# N32H49X register map
Vendor: Nsingtech Ltd.; File version: 1.0
Registers are 32-bit, read-write, reset 0x0 unless marked. A register's access mark holds for its fields unless they carry their own. Offsets are from the block's base; [hi:lo] are bit positions; {n}, {i} and the like mark numbered series.

## GPIOA — General purpose I/O
Base 0x4002C000
Same registers: GPIOB 0x4002C400, GPIOC 0x4002C800, GPIOD 0x4002CC00, GPIOE 0x4002D000, GPIOF 0x4002D400, GPIOG 0x4002D800
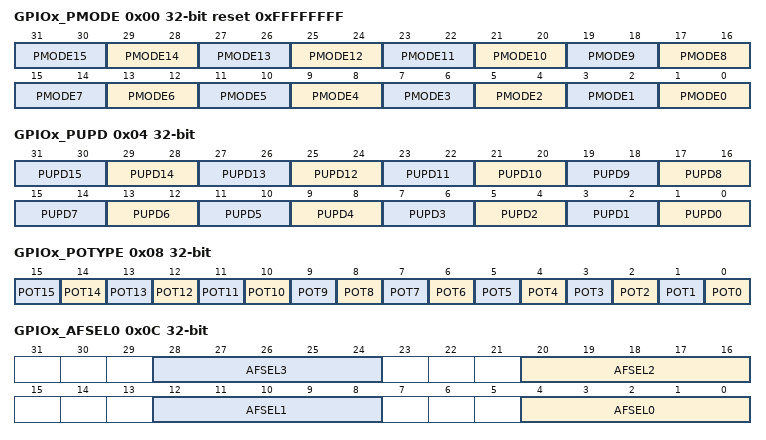
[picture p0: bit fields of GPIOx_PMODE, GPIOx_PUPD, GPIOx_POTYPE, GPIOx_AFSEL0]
0x00 GPIOx_PMODE reset 0xFFFFFFFF
  [2n+1:2n] PMODE{n} (n=0..15)
0x04 GPIOx_PUPD — GPIO pull-up/pull-down description register
  [2n+1:2n] PUPD{n} (n=0..15)
0x08 GPIOx_POTYPE — GPIO output type definition
  [n] POT{n} (n=0..15)
0x0C GPIOx_AFSEL0 — GPIO alternate function select register 0
  [8n+4:8n] AFSEL{n} (n=0..3)
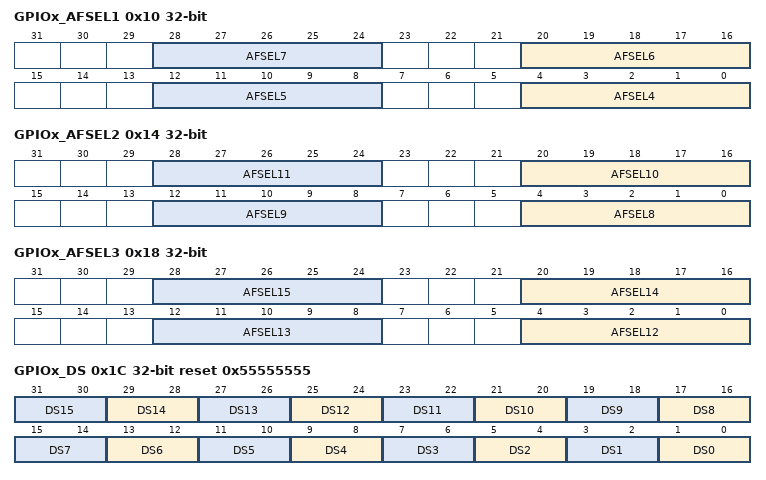
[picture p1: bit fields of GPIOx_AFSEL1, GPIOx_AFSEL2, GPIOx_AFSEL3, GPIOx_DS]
0x10 GPIOx_AFSEL1 — GPIO alternate function select register 1
  [8n-28:8n-32] AFSEL{n} (n=4..7)
0x14 GPIOx_AFSEL2 — GPIO alternate function select register 2
  [8n-60:8n-64] AFSEL{n} (n=8..11)
0x18 GPIOx_AFSEL3 — GPIO alternate function select register 3
  [8n-92:8n-96] AFSEL{n} (n=12..15)
0x1C GPIOx_DS reset 0x55555555 — GPIO driver strength configuration register
  [2n+1:2n] DS{n} (n=0..15)
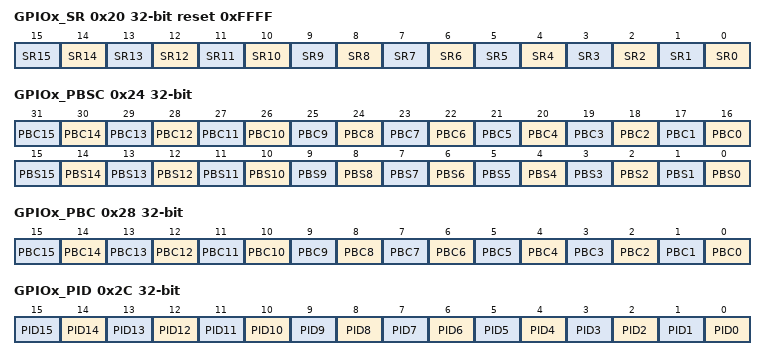
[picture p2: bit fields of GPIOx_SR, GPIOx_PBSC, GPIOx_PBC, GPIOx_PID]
0x20 GPIOx_SR reset 0xFFFF — GPIO slew rate configuration register
  [n] SR{n} (n=0..15)
0x24 GPIOx_PBSC wo — GPIO bit set/clear register
  [n+16] PBC{n} (n=0..15), [n] PBS{n} (n=0..15)
0x28 GPIOx_PBC wo — GPIO bit clear register
  [n] PBC{n} (n=0..15)
0x2C GPIOx_PID ro — GPIO input data register
  [n] PID{n} (n=0..15)
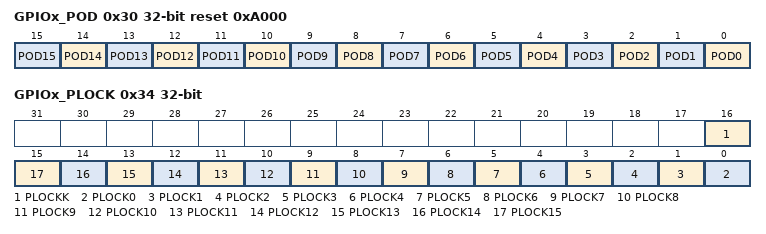
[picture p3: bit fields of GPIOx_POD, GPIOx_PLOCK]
0x30 GPIOx_POD reset 0xA000 — GPIO output data register
  [n] POD{n} (n=0..15)
0x34 GPIOx_PLOCK — GPIO configuration lock register
  [16] PLOCKK, [n] PLOCK{n} (n=0..15)

## GPIOH — General purpose I/O
Base 0x4002DC00
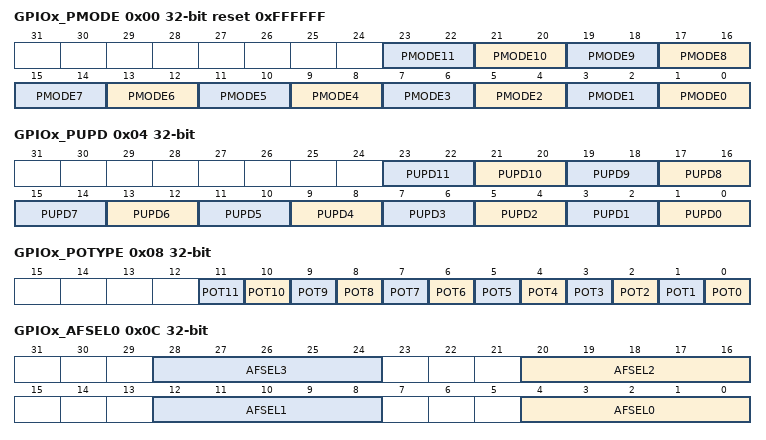
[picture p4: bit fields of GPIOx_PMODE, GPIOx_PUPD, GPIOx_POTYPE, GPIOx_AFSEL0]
0x00 GPIOx_PMODE reset 0xFFFFFF — GPIO mode description register
  [2n+1:2n] PMODE{n} (n=0..11)
0x04 GPIOx_PUPD — GPIO pull-up/pull-down description register
  [2n+1:2n] PUPD{n} (n=0..11)
0x08 GPIOx_POTYPE — GPIO output type definition
  [n] POT{n} (n=0..11)
0x0C GPIOx_AFSEL0 — GPIO alternate function select register 0
  [8n+4:8n] AFSEL{n} (n=0..3)
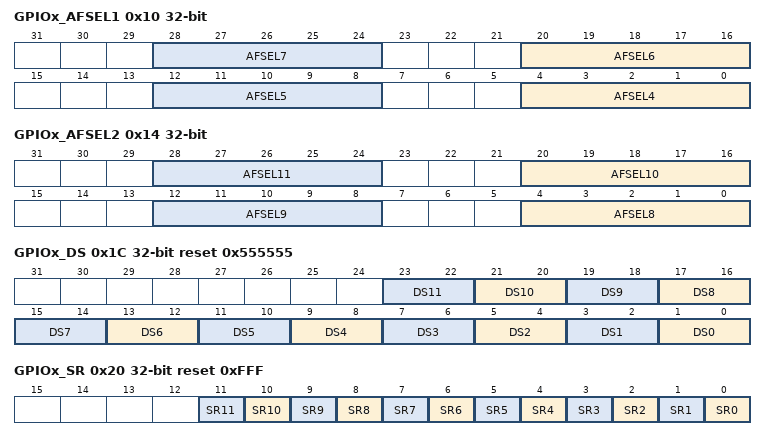
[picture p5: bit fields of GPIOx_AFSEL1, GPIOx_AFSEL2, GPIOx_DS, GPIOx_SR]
0x10 GPIOx_AFSEL1 — GPIO alternate function select register 1
  [8n-28:8n-32] AFSEL{n} (n=4..7)
0x14 GPIOx_AFSEL2 — GPIO alternate function select register 2
  [8n-60:8n-64] AFSEL{n} (n=8..11)
0x1C GPIOx_DS reset 0x555555 — GPIO driver strength configuration register
  [2n+1:2n] DS{n} (n=0..11)
0x20 GPIOx_SR reset 0xFFF — GPIO slew rate configuration register
  [n] SR{n} (n=0..11)
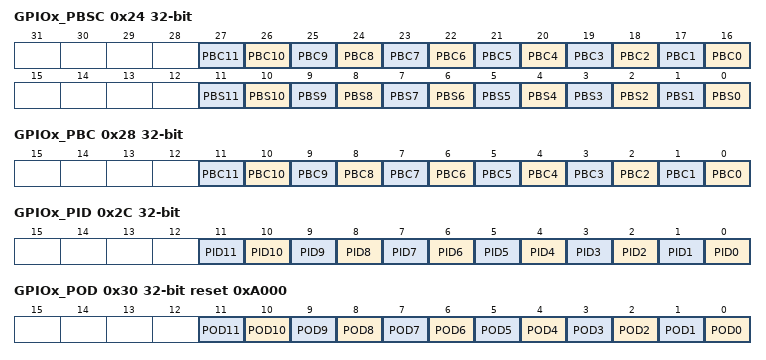
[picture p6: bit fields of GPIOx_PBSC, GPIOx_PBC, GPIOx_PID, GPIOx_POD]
0x24 GPIOx_PBSC wo — GPIO bit set/clear register
  [n+16] PBC{n} (n=0..11), [n] PBS{n} (n=0..11)
0x28 GPIOx_PBC wo — GPIO bit clear register
  [n] PBC{n} (n=0..11)
0x2C GPIOx_PID ro — GPIO input data register
  [n] PID{n} (n=0..11)
0x30 GPIOx_POD reset 0xA000 — GPIO output data register
  [n] POD{n} (n=0..11)
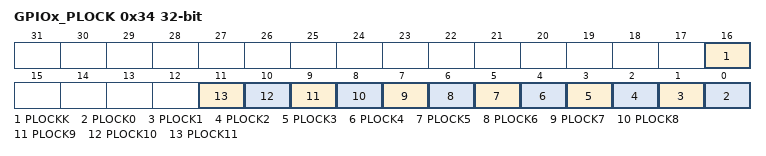
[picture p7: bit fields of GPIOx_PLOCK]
0x34 GPIOx_PLOCK — GPIO configuration lock register
  [16] PLOCKK, [n] PLOCK{n} (n=0..11)

## AFIO — Alternate function I/O
Base 0x40010800
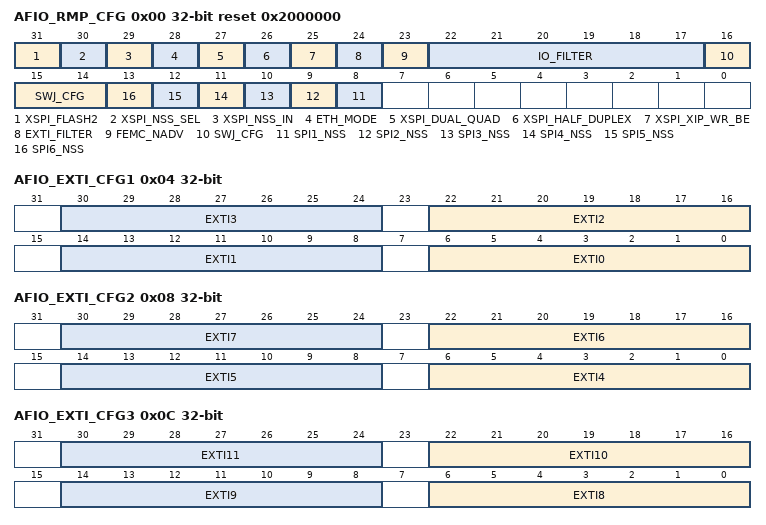
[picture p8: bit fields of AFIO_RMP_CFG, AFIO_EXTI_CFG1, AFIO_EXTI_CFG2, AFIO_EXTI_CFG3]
0x00 AFIO_RMP_CFG reset 0x2000000 — AFIO remapping configuration register
  [31] XSPI_FLASH2 — FLASH2 enable bit in XSPI Dual-Quad mode
  [30] XSPI_NSS_SEL — Select the valid NSS pin when NSS input is enabled in master mode
  [29] XSPI_NSS_IN — NSS input enable bit in master mode,it is used for multi-master test
  [28] ETH_MODE — ETH PHY interface mode configuration bit
  [27] XSPI_DUAL_QUAD — Dual-Quad mode enable bit
  [26] XSPI_HALF_DUPLEX — Half-Duplex mode enable bit
  [25] XSPI_XIP_WR_BE — Big endian enable bit in XIP mode
  [24] EXTI_FILTER — EXTI analog filter configuration bit
  [23] FEMC_NADV — FEMC NADV signal control bit
  [22:17] IO_FILTER — IO digital filter configuration bits
  [16:14] SWJ_CFG — Serial wire JTAG configuration bits
  [n+7] SPI{n}_NSS (n=1..6) — NSS state configuration bit for SPI{n} when idle
0x04 AFIO_EXTI_CFG1 — AFIO external interrupt configuration register 1
  [8n+6:8n] EXTI{n} (n=0..3)
0x08 AFIO_EXTI_CFG2 — AFIO external interrupt configuration register 2
  [8n-26:8n-32] EXTI{n} (n=4..7)
0x0C AFIO_EXTI_CFG3 — AFIO external interrupt configuration register 3
  [8n-58:8n-64] EXTI{n} (n=8..11)
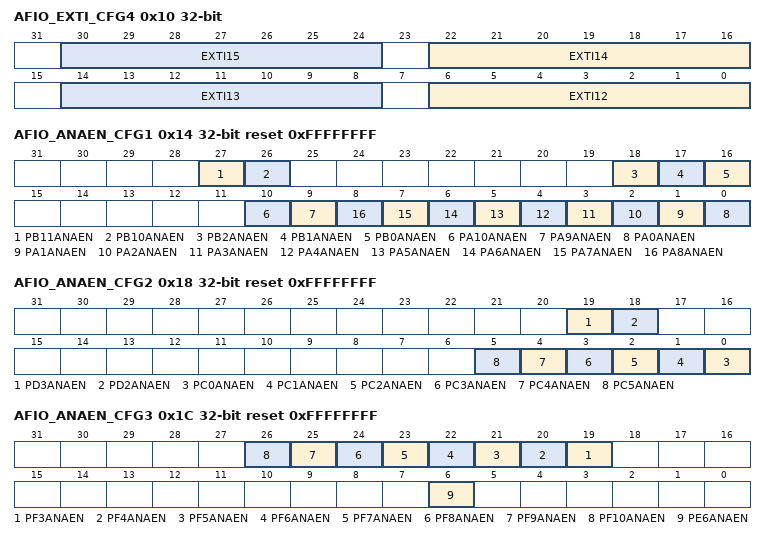
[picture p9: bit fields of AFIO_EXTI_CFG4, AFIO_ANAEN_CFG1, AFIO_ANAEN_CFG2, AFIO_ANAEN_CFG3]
0x10 AFIO_EXTI_CFG4 — AFIO external interrupt configuration register 4
  [8n-90:8n-96] EXTI{n} (n=12..15)
0x14 AFIO_ANAEN_CFG1 reset 0xFFFFFFFF — AFIO IO port analog signal channel configuration register 1
  [27] PB11ANAEN
  [26] PB10ANAEN
  [18] PB2ANAEN
  [17] PB1ANAEN
  [16] PB0ANAEN
  [10] PA10ANAEN — PA12ANAEN
  [9] PA9ANAEN — PA11ANAEN
  [n] PA{n}ANAEN (n=0..8)
0x18 AFIO_ANAEN_CFG2 reset 0xFFFFFFFF — AFIO IO port analog signal channel configuration register 2
  [19] PD3ANAEN, [18] PD2ANAEN, [n] PC{n}ANAEN (n=0..5)
0x1C AFIO_ANAEN_CFG3 reset 0xFFFFFFFF — AFIO IO port analog signal channel configuration register 3
  [n+16] PF{n}ANAEN (n=3..10), [6] PE6ANAEN
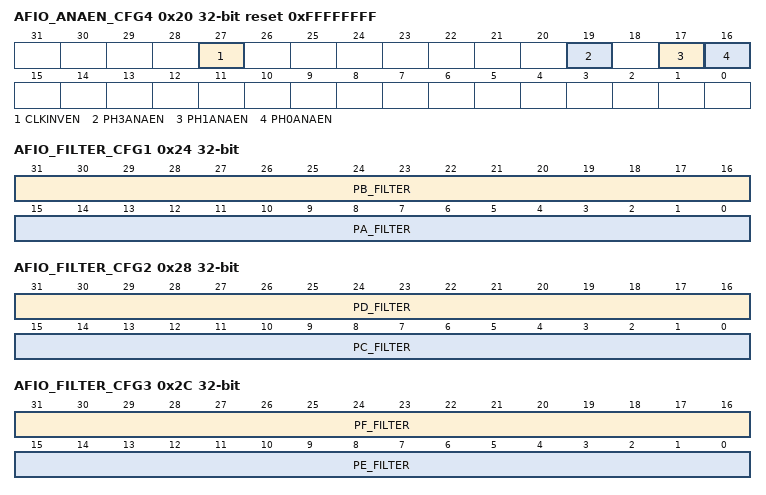
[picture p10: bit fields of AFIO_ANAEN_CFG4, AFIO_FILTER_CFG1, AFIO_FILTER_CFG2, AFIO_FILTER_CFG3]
0x20 AFIO_ANAEN_CFG4 reset 0xFFFFFFFF (reset mask 0xB0000) — AFIO IO port analog signal channel configuration register 4
  [27] CLKINVEN, [19] PH3ANAEN, [17] PH1ANAEN, [16] PH0ANAEN
0x24 AFIO_FILTER_CFG1 — AFIO IO port digtal filter configuration register 1
  [31:16] PB_FILTER, [15:0] PA_FILTER
0x28 AFIO_FILTER_CFG2 — AFIO IO port digtal filter configuration register 2
  [31:16] PD_FILTER, [15:0] PC_FILTER
0x2C AFIO_FILTER_CFG3 — AFIO IO port digtal filter configuration register 3
  [31:16] PF_FILTER, [15:0] PE_FILTER
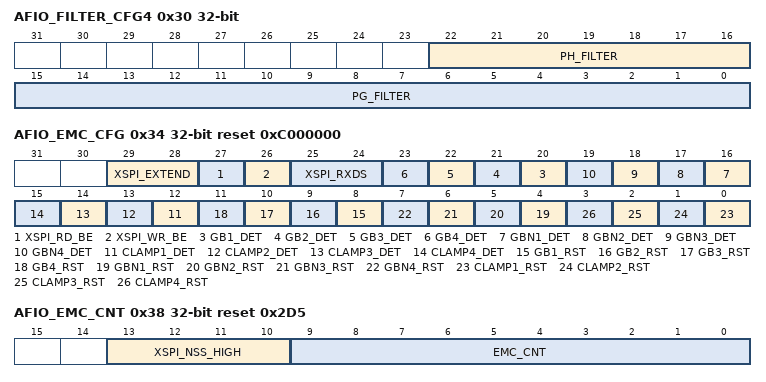
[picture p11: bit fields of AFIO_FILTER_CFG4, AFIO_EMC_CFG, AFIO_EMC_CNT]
0x30 AFIO_FILTER_CFG4 — AFIO IO port digtal filter configuration register 4
  [22:16] PH_FILTER, [15:0] PG_FILTER
0x34 AFIO_EMC_CFG reset 0xC000000 — AFIO EMC configuration register
  [29:28] XSPI_EXTEND — XSPI NSS setup time and hold time extension configuration bits
  [27] XSPI_RD_BE — Big endian enable bit for XSPI normal read operation (not XIP)
  [26] XSPI_WR_BE — Big endian enable bit for XSPI normal write operation (not XIP)
  [25:24] XSPI_RXDS — The data sample delay time for XSPI RXDS signal
  [n+19] GB{n}_DET (n=1..4)
  [n+15] GBN{n}_DET (n=1..4)
  [n+11] CLAMP{n}_DET (n=1..4)
  [n+7] GB{n}_RST (n=1..4)
  [n+3] GBN{n}_RST (n=1..4)
  [n-1] CLAMP{n}_RST (n=1..4)
0x38 AFIO_EMC_CNT reset 0x2D5 — AFIO EMC counter register
  [13:10] XSPI_NSS_HIGH — XSPI NSS high level time(idle) cofiguration bits
  [9:0] EMC_CNT — EMC error counter
